# APM32F423 register map
File version: 1.0
CPU: CM4 r1p0, little endian, no MPU, no FPU, 4 interrupt priority bits
Registers are 32-bit, read-write, reset 0x0 unless marked. A register's access mark holds for its fields unless they carry their own. Offsets are from the block's base; [hi:lo] are bit positions; {n}, {i} and the like mark numbered series; 'fields as' and 'values as' point back to an identical list.

## Ethernet_PTP — Ethernet: Precision time protocol
Base 0x40028700
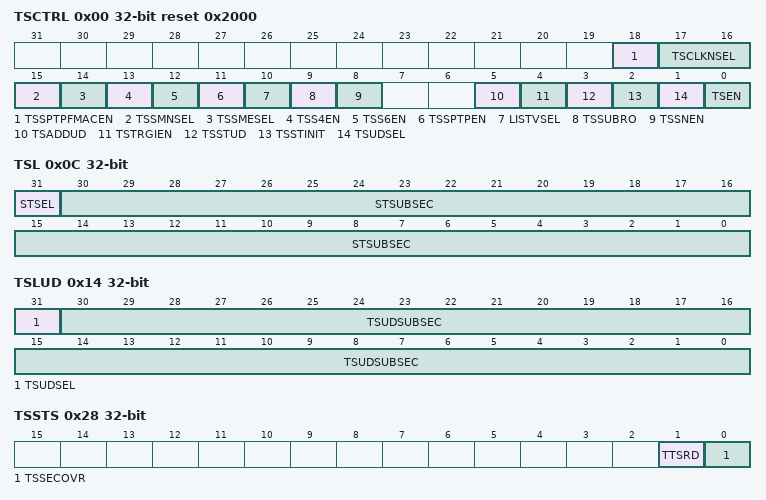
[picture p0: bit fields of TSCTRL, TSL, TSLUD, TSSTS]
0x00 TSCTRL reset 0x2000 — Ethernet PTP time stamp control register
  [18] TSSPTPFMACEN — Time Stamp PTP Frame Filtering MAC Address Enable
  [17:16] TSCLKNSEL — Time stamp Clock Node Select
  [15] TSSMNSEL — Time Stamp Snapshot for Master Node Select
  [14] TSSMESEL — Time Stamp Snapshot for Message Select
  [13] TSS4EN — Time Stamp Snapshot for IPv4 Frames Enable
  [12] TSS6EN — Time stamp snapshot for IPv6 frames Enable
  [11] TSSPTPEN — Time Stamp Snapshot for PTP Ethernet Frames Enable
  [10] LISTVSEL — Listening Version Select
  [9] TSSUBRO — Time Stamp Subsecond Rollover
  [8] TSSNEN — Time Stamp Snapshot for Received Frames Enable
  [5] TSADDUD — Time Stamp Addend Register Update
  [4] TSTRGIEN — Time Stamp Trigger Interrupt Enable
  [3] TSSTUD — Time Stamp System Time Update
  [2] TSSTINIT — Time Stamp System Time Initialize
  [1] TSUDSEL — Time Stamp Update Mode Select
  [0] TSEN — Time Stamp Enable
0x04 SUBSECI — Ethernet PTP subsecond increment register
  [7:0] STSUBSECI — System Time Subseconds Incremen
0x08 TSH ro — Ethernet PTP time stamp high register
  [31:0] STSEC — System Time Second Value
0x0C TSL ro — Ethernet PTP time stamp low register
  [31] STSEL — System Time Select
  [30:0] STSUBSEC — System Time Subseconds Value
0x10 TSHUD — Ethernet PTP time stamp high update register
  [31:0] TSUDSEC — Time Stamp Update Second Value
0x14 TSLUD — Ethernet PTP time stamp low update register
  [31] TSUDSEL — Time Stamp Update Select
  [30:0] TSUDSUBSEC — Time Stamp Update Subseconds Value
0x18 TSA — Ethernet PTP time stamp addend register
  [31:0] TSA — Time Stamp Addend Value
0x1C TTSH — Ethernet PTP target time high register
  [31:0] TTSH — Target Time Stamp High Value
0x20 TTSL — Ethernet PTP target time low register
  [31:0] TTSL — Target Time Stamp Low Value
0x28 TSSTS ro — Ethernet PTP time stamp status register
  [1] TTSRD — Target Time Stamp Value Reached
  [0] TSSECOVR — Time Stamp Second Value Overflow
0x2C PPSCTRL ro — Ethernet PTP PPS control register
  [3:0] PPSFSEL — PPS Frequency Selection

## OTG_FS1_HOST — USB on the go full speed
Base 0x50000400
Same registers: OTG_FS2_HOST 0x40040400
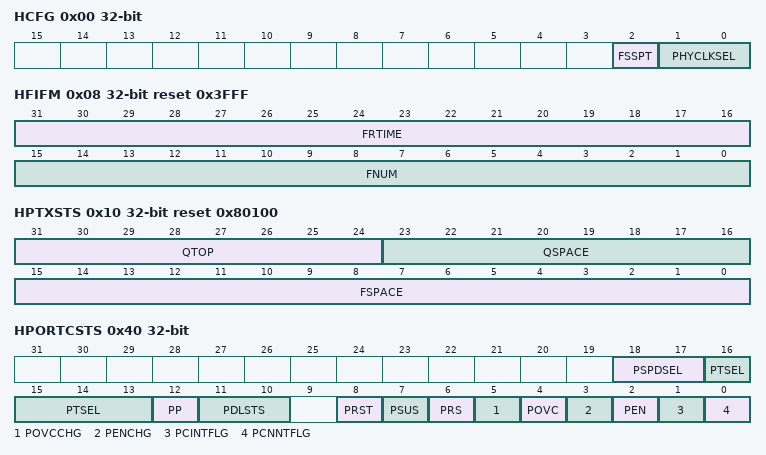
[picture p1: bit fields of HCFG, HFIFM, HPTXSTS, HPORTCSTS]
0x00 HCFG access per field — OTG_FS host configuration register (OTG_FS_HCFG)
  [2] FSSPT ro — FS- and LS-only support
  [1:0] PHYCLKSEL rw — FS/LS PHY clock select
0x04 HFIVL reset 0xEA60 — OTG_FS Host frame interval register
  [15:0] FIVL — Frame interval
0x08 HFIFM ro reset 0x3FFF — OTG_FS host frame number/frame time remaining register (OTG_FS_HFNUM)
  [31:16] FRTIME — Frame time remaining
  [15:0] FNUM — Frame number
0x10 HPTXSTS access per field reset 0x80100 — OTG_FS_Host periodic transmit FIFO/queue status register (OTG_FS_HPTXSTS)
  [31:24] QTOP ro — Top of the periodic transmit request queue
  [23:16] QSPACE ro — Periodic transmit request queue space available
  [15:0] FSPACE rw — Periodic transmit data FIFO space available
0x14 HACHINT ro — OTG_FS Host all channels interrupt register
  [15:0] ACHINT — Channel interrupts
0x18 HACHIMASK — OTG_FS host all channels interrupt mask register
  [15:0] ACHIMASK — Channel interrupt mask
0x40 HPORTCSTS access per field — OTG_FS host port control and status register (OTG_FS_HPRT)
  [18:17] PSPDSEL ro — Port speed
  [16:13] PTSEL rw — Port test control
  [12] PP rw — Port power
  [11:10] PDLSTS ro — Port line status
  [8] PRST rw — Port reset
  [7] PSUS rw — Port suspend
  [6] PRS rw — Port resume
  [5] POVCCHG rw — Port overcurrent change
  [4] POVC ro — Port overcurrent active
  [3] PENCHG rw — Port enable/disable change
  [2] PEN rw — Port enable
  [1] PCINTFLG rw — Port connect detected
  [0] PCNNTFLG ro — Port connect status
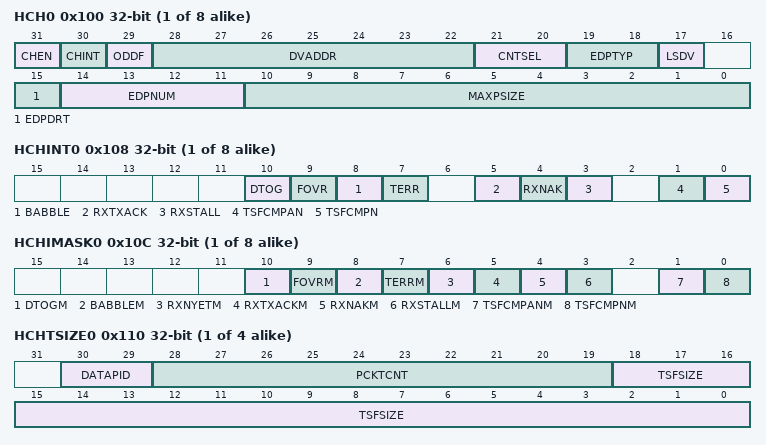
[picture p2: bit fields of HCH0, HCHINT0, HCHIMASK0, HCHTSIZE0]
{0x100+0x20*i} HCH{i} (i=0..7) — OTG_FS host channel-{i} characteristics register (OTG_FS_HCCHAR{i})
  [31] CHEN — Channel enable
  [30] CHINT — Channel disable
  [29] ODDF — Odd frame
  [28:22] DVADDR — Device address
  [21:20] CNTSEL — Multicount
  [19:18] EDPTYP — Endpoint type
  [17] LSDV — Low-speed device
  [15] EDPDRT — Endpoint direction
  [14:11] EDPNUM — Endpoint number
  [10:0] MAXPSIZE — Maximum packet size
{0x108+0x20*i} HCHINT{i} (i=0..7) — OTG_FS host channel-{i} interrupt register (OTG_FS_HCINT{i})
  [10] DTOG — Data toggle error
  [9] FOVR — Frame overrun
  [8] BABBLE — Babble error
  [7] TERR — Transaction error
  [5] RXTXACK — ACK response received/transmitted interrupt
  [4] RXNAK — NAK response received interrupt
  [3] RXSTALL — STALL response received interrupt
  [1] TSFCMPAN — Channel halted
  [0] TSFCMPN — Transfer completed
{0x10C+0x20*i} HCHIMASK{i} (i=0..7) — OTG_FS host channel-{i} mask register (OTG_FS_HCINTMSK{i})
  [10] DTOGM — Data toggle error mask
  [9] FOVRM — Frame overrun mask
  [8] BABBLEM — Babble error mask
  [7] TERRM — Transaction error mask
  [6] RXNYETM — response received interrupt mask
  [5] RXTXACKM — ACK response received/transmitted interrupt mask
  [4] RXNAKM — NAK response received interrupt mask
  [3] RXSTALLM — STALL response received interrupt mask
  [1] TSFCMPANM — Channel halted mask
  [0] TSFCMPNM — Transfer completed mask
{0x110+0x20*i} HCHTSIZE{i} (i=0..3) — OTG_FS host channel-{i} transfer size register
  [30:29] DATAPID
  [28:19] PCKTCNT — Packet count
  [18:0] TSFSIZE — Transfer size
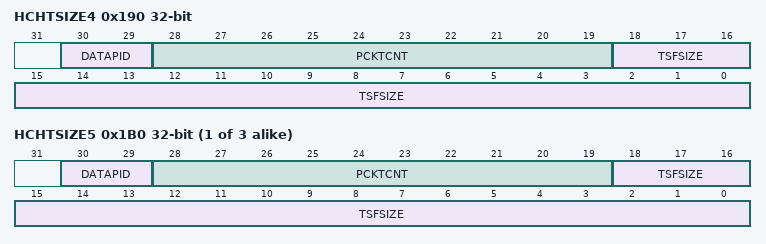
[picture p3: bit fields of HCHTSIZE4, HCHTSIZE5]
0x190 HCHTSIZE4 — OTG_FS host channel-x transfer size register
  fields as HCHTSIZE0
{0x110+0x20*i} HCHTSIZE{i} (i=5..7) — OTG_FS host channel-{i} transfer size register
  fields as HCHTSIZE0

## OTG_FS1_PWRCLK — USB on the go full speed
Base 0x50000E00
Same registers: OTG_FS2_PWRCLK 0x40040E00
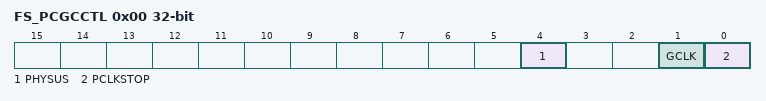
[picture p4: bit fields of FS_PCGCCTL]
0x00 FS_PCGCCTL — OTG_FS power and clock gating control register
  [4] PHYSUS — PHY Suspended
  [1] GCLK — Gate HCLK
  [0] PCLKSTOP — Stop PHY clock
